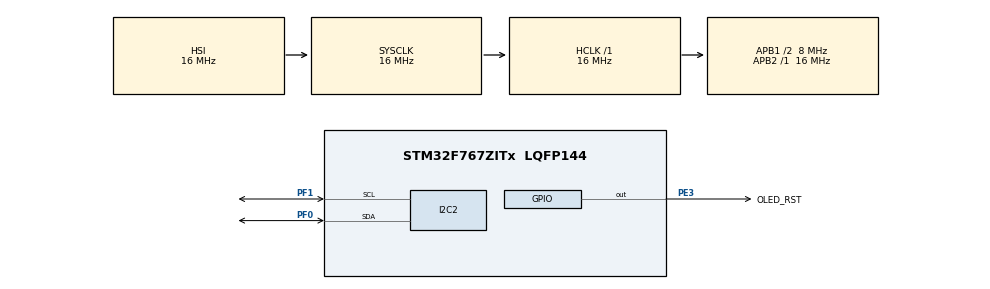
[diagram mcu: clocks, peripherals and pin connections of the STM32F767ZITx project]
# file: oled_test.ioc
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I2C2.Timing=0x2000090E
Mcu.Family=STM32F7
Mcu.Name=STM32F767ZITx
Mcu.Package=LQFP144
NVIC.PriorityGroup=NVIC_PRIORITYGROUP_4
PA13.Mode=Serial_Wire
PA13.Signal=SYS_JTMS-SWDIO
PA14.Mode=Serial_Wire
PA14.Signal=SYS_JTCK-SWCLK
PE3.GPIO_Label=OLED_RST
PE3.Signal=GPIO_Output
PF0.Mode=I2C
PF0.Signal=I2C2_SDA
PF1.Mode=I2C
PF1.Signal=I2C2_SCL
ProjectManager.HeapSize=0x200
ProjectManager.StackSize=0x400
ProjectManager.TargetToolchain=MDK-ARM V5
RCC.48MHZClocksFreq_Value=24000000
RCC.AHBFreq_Value=16000000
RCC.APB1CLKDivider=RCC_HCLK_DIV2
RCC.APB1Freq_Value=8000000
RCC.APB1TimFreq_Value=16000000
RCC.APB2Freq_Value=16000000
RCC.APB2TimFreq_Value=16000000
RCC.CortexFreq_Value=16000000
RCC.HCLKFreq_Value=16000000
RCC.HSE_VALUE=16000000
RCC.HSI_VALUE=16000000
RCC.LSE_VALUE=32768
RCC.PLLMUL=RCC_PLL_MUL9
RCC.PRESCALERUSB=RCC_USBCLKSOURCE_PLL_DIV1_5
RCC.SYSCLKFreq_VALUE=16000000
RCC.SYSCLKSourceVirtual=RCC_SYSCLKSOURCE_PLLCLK
RCC.USBFreq_Value=96000000
RCC.VCOOutputFreq_Value=192000000
board=NUCLEO-F767ZI

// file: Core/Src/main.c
/* USER CODE BEGIN Header */
/**
  ******************************************************************************
  * @file           : main.c
  * @brief          : Main program body
  ******************************************************************************
  * @attention
  *
  * <h2><center>&copy; Copyright (c) 2019 STMicroelectronics.
  * All rights reserved.</center></h2>
  *
  * This software component is licensed by ST under BSD 3-Clause license,
  * the "License"; You may not use this file except in compliance with the
  * License. You may obtain a copy of the License at:
  *                        opensource.org/licenses/BSD-3-Clause
  *
  ******************************************************************************
  */
/* USER CODE END Header */

#include "main.h"
#include "i2c.h"
#include "gpio.h"

/* USER CODE BEGIN Includes */
#include "ssd1306.h"
#include <string.h>
#include <stdio.h>
/* USER CODE END Includes */

void SystemClock_Config(void);

/* USER CODE BEGIN 0 */
void ssd1306_TestBorder() {
    ssd1306_Fill(Black);

    uint32_t start = HAL_GetTick();
    uint32_t end = start;
    uint8_t x = 0;
    uint8_t y = 0;
    do {
        ssd1306_DrawPixel(x, y, Black);

        if((y == 0) && (x < 127))
            x++;
        else if((x == 127) && (y < 63))
            y++;
        else if((y == 63) && (x > 0))
            x--;
        else
            y--;

        ssd1306_DrawPixel(x, y, White);
        ssd1306_UpdateScreen();

        HAL_Delay(5);
        end = HAL_GetTick();
    } while((end - start) < 8000);

    HAL_Delay(1000);
}

void ssd1306_TestFonts() {
    ssd1306_Fill(Black);
    ssd1306_SetCursor(2, 0);
    ssd1306_WriteString("Font 16x26", Font_16x26, White);
    ssd1306_SetCursor(2, 26);
    ssd1306_WriteString("Font 11x18", Font_11x18, White);
    ssd1306_SetCursor(2, 26+18);
    ssd1306_WriteString("Font 7x10", Font_7x10, White);
    ssd1306_UpdateScreen();
}

void ssd1306_TestFPS() {
    ssd1306_Fill(White);

    uint32_t start = HAL_GetTick();
    uint32_t end = start;
    int fps = 0;
    char message[] = "ABCDEFGHIJK";

    ssd1306_SetCursor(2,0);
    ssd1306_WriteString("Testing...", Font_11x18, Black);

    do {
        ssd1306_SetCursor(2, 18);
        ssd1306_WriteString(message, Font_11x18, Black);
        ssd1306_UpdateScreen();

        char ch = message[0];
        memmove(message, message+1, sizeof(message)-2);
        message[sizeof(message)-2] = ch;

        fps++;
        end = HAL_GetTick();
    } while((end - start) < 5000);

    HAL_Delay(1000);

    char buff[64];
    fps = (float)fps / ((end - start) / 1000.0);
    snprintf(buff, sizeof(buff), "~%d FPS", fps);

    ssd1306_Fill(White);
    ssd1306_SetCursor(2, 18);
    ssd1306_WriteString(buff, Font_11x18, Black);
    ssd1306_UpdateScreen();
}

void ssd1306_TestAll() {
    ssd1306_Init();
    ssd1306_TestFPS();
    HAL_Delay(3000);
    ssd1306_TestBorder();
    ssd1306_TestFonts();
}

void ssd1306_Testairquam1() {

	ssd1306_Fill(Black);

  ssd1306_SetCursor(4, 2);
	ssd1306_WriteString("    23:59:59", Font_7x10, White);

	ssd1306_SetCursor(0, 24); ssd1306_WriteString("   NO2: 0.45ppm", Font_7x10, White);
	ssd1306_SetCursor(0, 34); ssd1306_WriteString("    CO: 50ppm", Font_7x10, White);
	ssd1306_SetCursor(0, 44); ssd1306_WriteString("   CO2: 600ppm", Font_7x10, White);
	ssd1306_SetCursor(0, 54); ssd1306_WriteString("  TVOC: 600ppb", Font_7x10, White);

	ssd1306_SetCursor(113, 0);
	ssd1306_drawIcon(Icon_wlan, White);

	ssd1306_SetCursor(96, 0);
	ssd1306_drawIcon(Icon_satellite, White);

	for(int i=0; i<20; i++)
		for(int j=0; j<11; j++)
			ssd1306_DrawPixel(i, j, White);

	ssd1306_SetCursor(4, 2);
	ssd1306_WriteString("ON", Font_7x10, Black);
	for(int i=0; i<=20; i++)	{
		ssd1306_DrawPixel(i, 0, White);
		ssd1306_DrawPixel(i, 11, White);
	}
	for(int i=0; i<=11; i++)	{
		ssd1306_DrawPixel(20, i, White);
		ssd1306_DrawPixel(0, i, White);
	}

    ssd1306_UpdateScreen();

}

void ssd1306_Testairquam2() {

	ssd1306_Fill(Black);

  ssd1306_SetCursor(4, 2);
	ssd1306_WriteString("   31-12-2019", Font_7x10, White);

	ssd1306_SetCursor(0, 24); ssd1306_WriteString("T: 25'C   RH: 50%", Font_7x10, White);
	ssd1306_SetCursor(0, 34); ssd1306_WriteString("    Ts: 5 s", Font_7x10, White);
	ssd1306_SetCursor(0, 44); ssd1306_WriteString(" N  90.12345678", Font_7x10, White);
	ssd1306_SetCursor(0, 54); ssd1306_WriteString(" W 180.12345678", Font_7x10, White);

	ssd1306_SetCursor(113, 0);
	ssd1306_drawIcon(Icon_wlan, White);

	ssd1306_SetCursor(96, 0);
	ssd1306_drawIcon(Icon_satellite, White);

	ssd1306_SetCursor(0, 2);
	ssd1306_WriteString("OFF", Font_7x10, White);
	for(int i=0; i<=20; i++)	{
		ssd1306_DrawPixel(i, 0, White);
		ssd1306_DrawPixel(i, 11, White);
	}
	for(int i=0; i<=11; i++)	{
		ssd1306_DrawPixel(20, i, White);
		ssd1306_DrawPixel(0, i, White);
	}

  ssd1306_UpdateScreen();

}

void ssd1306_Testsplash() {

	ssd1306_Fill(Black);

  ssd1306_SetCursor(8, 18);
	ssd1306_WriteString("AirQuaM12345", Font_16x26, White);

  ssd1306_UpdateScreen();

}
/* USER CODE END 0 */

int main(void)
{

  /* MCU Configuration--------------------------------------------------------*/

  /* Reset of all peripherals, Initializes the Flash interface and the Systick. */
  HAL_Init();

  /* Configure the system clock */
  SystemClock_Config();

  /* Initialize all configured peripherals */
  MX_GPIO_Init();
  MX_I2C2_Init();
  /* USER CODE BEGIN 2 */
		HAL_GPIO_WritePin(OLED_RST_GPIO_Port, OLED_RST_Pin, GPIO_PIN_RESET);
	HAL_GPIO_WritePin(OLED_RST_GPIO_Port, OLED_RST_Pin, GPIO_PIN_SET);
	  //ssd1306_TestAll();

  /* USER CODE END 2 */

  /* Infinite loop */
  /* USER CODE BEGIN WHILE */
	ssd1306_Init();
	ssd1306_Testsplash();
	HAL_Delay(1000);
  while (1)
  {
		ssd1306_Testairquam1();
		HAL_Delay(5000);
		ssd1306_Testairquam2();
		HAL_Delay(5000);
    /* USER CODE END WHILE */

  }
}

void SystemClock_Config(void)
{
  RCC_OscInitTypeDef RCC_OscInitStruct = {0};
  RCC_ClkInitTypeDef RCC_ClkInitStruct = {0};
  RCC_PeriphCLKInitTypeDef PeriphClkInitStruct = {0};

  /** Configure the main internal regulator output voltage
  */
  __HAL_RCC_PWR_CLK_ENABLE();
  __HAL_PWR_VOLTAGESCALING_CONFIG(PWR_REGULATOR_VOLTAGE_SCALE3);
  /** Initializes the CPU, AHB and APB busses clocks
  */
  RCC_OscInitStruct.OscillatorType = RCC_OSCILLATORTYPE_HSI;
  RCC_OscInitStruct.HSIState = RCC_HSI_ON;
  RCC_OscInitStruct.HSICalibrationValue = RCC_HSICALIBRATION_DEFAULT;
  RCC_OscInitStruct.PLL.PLLState = RCC_PLL_NONE;
  if (HAL_RCC_OscConfig(&RCC_OscInitStruct) != HAL_OK)
  {
    Error_Handler();
  }
  /** Initializes the CPU, AHB and APB busses clocks
  */
  RCC_ClkInitStruct.ClockType = RCC_CLOCKTYPE_HCLK|RCC_CLOCKTYPE_SYSCLK
                              |RCC_CLOCKTYPE_PCLK1|RCC_CLOCKTYPE_PCLK2;
  RCC_ClkInitStruct.SYSCLKSource = RCC_SYSCLKSOURCE_HSI;
  RCC_ClkInitStruct.AHBCLKDivider = RCC_SYSCLK_DIV1;
  RCC_ClkInitStruct.APB1CLKDivider = RCC_HCLK_DIV2;
  RCC_ClkInitStruct.APB2CLKDivider = RCC_HCLK_DIV1;

  if (HAL_RCC_ClockConfig(&RCC_ClkInitStruct, FLASH_LATENCY_0) != HAL_OK)
  {
    Error_Handler();
  }
  PeriphClkInitStruct.PeriphClockSelection = RCC_PERIPHCLK_I2C2;
  PeriphClkInitStruct.I2c2ClockSelection = RCC_I2C2CLKSOURCE_PCLK1;
  if (HAL_RCCEx_PeriphCLKConfig(&PeriphClkInitStruct) != HAL_OK)
  {
    Error_Handler();
  }
}

void Error_Handler(void)
{
}

/************************ (C) COPYRIGHT STMicroelectronics *****END OF FILE****/
